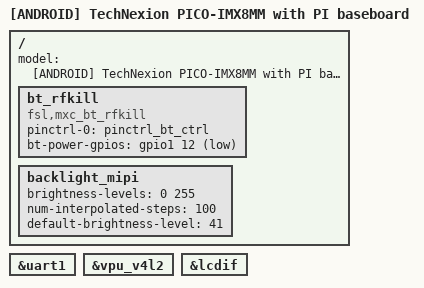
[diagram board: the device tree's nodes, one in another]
// SPDX-License-Identifier: (GPL-2.0+ OR MIT)
/*
 * Copyright 2020 Technexion Ltd.
 *
 * Author: Tifa Chen <tifa.chen@technexion.com>
 *
 */

 /dts-v1/;

#include "imx8mm-pico-pi.dts"
#include "imx8mm-android.dtsi"

/ {
	model = "[ANDROID] TechNexion PICO-IMX8MM with PI baseboard";

	/delete-node/ bt_reg_on;
	bt_rfkill {
		compatible = "fsl,mxc_bt_rfkill";
		pinctrl-0 = <&pinctrl_bt_ctrl>;
		bt-power-gpios = <&gpio1 12 GPIO_ACTIVE_LOW>;
		status ="okay";
	};

	backlight_mipi {
		brightness-levels = <0 255>;
		num-interpolated-steps = <100>;
		default-brightness-level = <41>;
	};
};

&uart1 {
	/delete-property/ resets;
};

&vpu_v4l2 {
	status = "okay";
};

&lcdif {
	/delete-property/ trusty;
};
